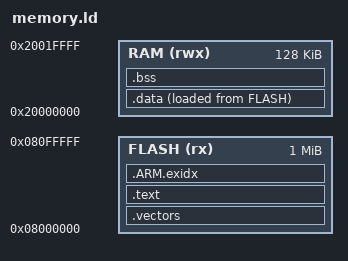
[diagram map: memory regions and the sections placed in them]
ENTRY(Reset_Handler)
MEMORY {
    FLASH (rx) : ORIGIN = 0x08000000, LENGTH = 1024K
    RAM (rwx) : ORIGIN = 0x20000000, LENGTH = 128K
}
_estack = ORIGIN(RAM) + LENGTH(RAM);
SECTIONS {
    .vectors : { KEEP(*(.vectors)) } > FLASH
    .text : { *(.text*) *(.rodata*) } > FLASH
    .ARM.exidx : { *(.ARM.exidx*) } > FLASH
    .data : {
        _sdata = .; *(.data*) . = ALIGN(4); _edata = .;
    } > RAM AT> FLASH
    _sidata = LOADADDR(.data);
    .bss (NOLOAD) : {
        . = ALIGN(4); _sbss = .; *(.bss*) *(COMMON) . = ALIGN(4); _ebss = .;
    } > RAM
    end = .;
    _end = .;
    ASSERT(_ebss < _estack - 16384, "Test image must leave 16K for stack/heap")
}
